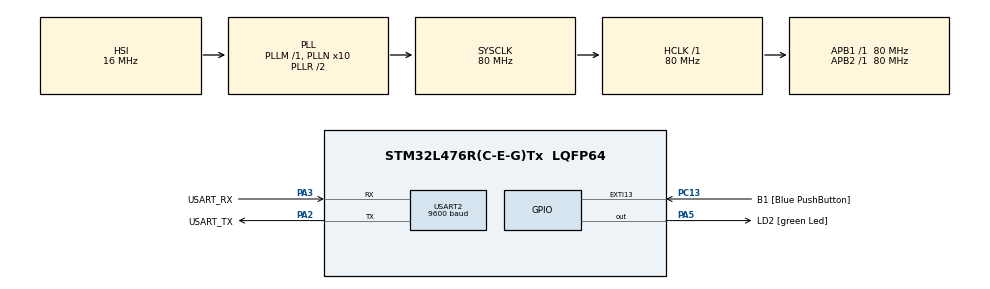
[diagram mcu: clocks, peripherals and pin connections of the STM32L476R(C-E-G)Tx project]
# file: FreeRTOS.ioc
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Mcu.Family=STM32L4
PA2.GPIO_PuPd=GPIO_NOPULL
VP_SYS_VS_tim6.Mode=TIM6
RCC.CortexFreq_Value=80000000
NVIC.TIM6_DAC_IRQn=true\:0\:0\:false\:false\:true\:false\:false\:true
PH0-OSC_IN\ (PH0).Signal=RCC_OSC_IN
PA3.GPIO_PuPd=GPIO_NOPULL
PA2.GPIO_Speed=GPIO_SPEED_FREQ_VERY_HIGH
PC15-OSC32_OUT\ (PC15).Mode=LSE-External-Oscillator
PC13.GPIO_Label=B1 [Blue PushButton]
PA3.GPIO_Speed=GPIO_SPEED_FREQ_VERY_HIGH
RCC.SYSCLKSource=RCC_SYSCLKSOURCE_PLLCLK
ProjectManager.StackSize=0x400
PB3\ (JTDO-TRACESWO).Signal=SYS_JTDO-SWO
PC14-OSC32_IN\ (PC14).Mode=LSE-External-Oscillator
VP_FREERTOS_VS_CMSIS_V2.Mode=CMSIS_V2
PA14\ (JTCK-SWCLK).Signal=SYS_JTCK-SWCLK
RCC.HCLKFreq_Value=80000000
RCC.APB2TimFreq_Value=80000000
RCC.AHBFreq_Value=80000000
RCC.PREFETCH_ENABLE=1
RCC.HSE_VALUE=8000000
USART2.VirtualMode-Asynchronous=VM_ASYNC
PA5.GPIO_PuPd=GPIO_NOPULL
PC13.GPIO_PuPd=GPIO_NOPULL
Mcu.Package=LQFP64
NVIC.TimeBase=TIM6_DAC_IRQn
PA2.GPIO_Label=USART_TX
NVIC.TimeBaseIP=TIM6
RCC.APB1TimFreq_Value=80000000
PA13\ (JTMS-SWDIO).Signal=SYS_JTMS-SWDIO
PA3.Signal=USART2_RX
PA2.GPIO_Mode=GPIO_MODE_AF_PP
RCC.MSI_VALUE=4000000
RCC.PLLSourceVirtual=RCC_PLLSOURCE_HSI
PA14\ (JTCK-SWCLK).Mode=Serial_Wire
FREERTOS.Tasks01=blink01,24,128,StartBlink01,Default,NULL,Dynamic,NULL,NULL;blink02,16,128,StartBlink02,Default,NULL,Dynamic,NULL,NULL
PC13.Signal=GPXTI13
PC15-OSC32_OUT\ (PC15).Signal=RCC_OSC32_OUT
PA14\ (JTCK-SWCLK).GPIO_Label=TCK
PB3\ (JTDO-TRACESWO).GPIO_Label=SWO
USART2.BaudRate=9600
PH1-OSC_OUT\ (PH1).Signal=RCC_OSC_OUT
PA3.Mode=Asynchronous
ProjectManager.TargetToolchain=STM32CubeIDE
PA3.GPIO_Mode=GPIO_MODE_AF_PP
RCC.USBFreq_Value=64000000
PA5.Signal=GPIO_Output
board=NUCLEO-L476RG
RCC.VCOOutputFreq_Value=160000000
RCC.APB2Freq_Value=80000000
PA5.GPIO_ModeDefaultOutputPP=GPIO_MODE_OUTPUT_PP
PA13\ (JTMS-SWDIO).GPIO_Label=TMS
RCC.ADCFreq_Value=64000000
Mcu.Name=STM32L476R(C-E-G)Tx
PA2.Signal=USART2_TX
PA13\ (JTMS-SWDIO).Mode=Serial_Wire
RCC.SYSCLKFreq_VALUE=80000000
PA5.GPIO_Label=LD2 [green Led]
PC13.GPIO_ModeDefaultEXTI=GPIO_MODE_IT_FALLING
PC14-OSC32_IN\ (PC14).Signal=RCC_OSC32_IN
ProjectManager.HeapSize=0x200
RCC.HSI_VALUE=16000000
PA5.GPIO_Speed=GPIO_SPEED_FREQ_LOW
NVIC.PriorityGroup=NVIC_PRIORITYGROUP_4
RCC.PLLN=10
PA2.Mode=Asynchronous
RCC.APB1Freq_Value=80000000
PA3.GPIO_Label=USART_RX

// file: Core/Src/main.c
/* USER CODE BEGIN Header */
/**
  ******************************************************************************
  * @file           : main.c
  * @brief          : Main program body
  ******************************************************************************
  * @attention
  *
  * <h2><center>&copy; Copyright (c) 2021 STMicroelectronics.
  * All rights reserved.</center></h2>
  *
  * This software component is licensed by ST under BSD 3-Clause license,
  * the "License"; You may not use this file except in compliance with the
  * License. You may obtain a copy of the License at:
  *                        opensource.org/licenses/BSD-3-Clause
  *
  ******************************************************************************
  */
/* USER CODE END Header */
#include "main.h"
#include "cmsis_os.h"

/* USER CODE BEGIN Includes */
#include "debug.h"
/* USER CODE END Includes */

UART_HandleTypeDef huart2;

/* Definitions for blink01 */
osThreadId_t blink01Handle;
const osThreadAttr_t blink01_attributes = {
  .name = "blink01",
  .stack_size = 128 * 4,
  .priority = (osPriority_t) osPriorityNormal,
};
/* Definitions for blink02 */
osThreadId_t blink02Handle;
const osThreadAttr_t blink02_attributes = {
  .name = "blink02",
  .stack_size = 128 * 4,
  .priority = (osPriority_t) osPriorityBelowNormal,
};

void SystemClock_Config(void);
static void MX_GPIO_Init(void);
static void MX_USART2_UART_Init(void);
void StartBlink01(void *argument);
void StartBlink02(void *argument);

int main(void)
{

  /* MCU Configuration--------------------------------------------------------*/

  /* Reset of all peripherals, Initializes the Flash interface and the Systick. */
  HAL_Init();

  /* Configure the system clock */
  SystemClock_Config();

  /* Initialize all configured peripherals */
  MX_GPIO_Init();
  MX_USART2_UART_Init();

  /* Init scheduler */
  osKernelInitialize();

  /* Create the thread(s) */
  /* creation of blink01 */
  blink01Handle = osThreadNew(StartBlink01, NULL, &blink01_attributes);

  /* creation of blink02 */
  blink02Handle = osThreadNew(StartBlink02, NULL, &blink02_attributes);

  /* Start scheduler */
  osKernelStart();

  /* We should never get here as control is now taken by the scheduler */
  /* Infinite loop */
  while (1)
  {

  }
}

void SystemClock_Config(void)
{
  RCC_OscInitTypeDef RCC_OscInitStruct = {0};
  RCC_ClkInitTypeDef RCC_ClkInitStruct = {0};
  RCC_PeriphCLKInitTypeDef PeriphClkInit = {0};

  /** Initializes the RCC Oscillators according to the specified parameters
  * in the RCC_OscInitTypeDef structure.
  */
  RCC_OscInitStruct.OscillatorType = RCC_OSCILLATORTYPE_HSI;
  RCC_OscInitStruct.HSIState = RCC_HSI_ON;
  RCC_OscInitStruct.HSICalibrationValue = RCC_HSICALIBRATION_DEFAULT;
  RCC_OscInitStruct.PLL.PLLState = RCC_PLL_ON;
  RCC_OscInitStruct.PLL.PLLSource = RCC_PLLSOURCE_HSI;
  RCC_OscInitStruct.PLL.PLLM = 1;
  RCC_OscInitStruct.PLL.PLLN = 10;
  RCC_OscInitStruct.PLL.PLLP = RCC_PLLP_DIV7;
  RCC_OscInitStruct.PLL.PLLQ = RCC_PLLQ_DIV2;
  RCC_OscInitStruct.PLL.PLLR = RCC_PLLR_DIV2;
  if (HAL_RCC_OscConfig(&RCC_OscInitStruct) != HAL_OK)
  {
    Error_Handler();
  }
  /** Initializes the CPU, AHB and APB buses clocks
  */
  RCC_ClkInitStruct.ClockType = RCC_CLOCKTYPE_HCLK|RCC_CLOCKTYPE_SYSCLK
                              |RCC_CLOCKTYPE_PCLK1|RCC_CLOCKTYPE_PCLK2;
  RCC_ClkInitStruct.SYSCLKSource = RCC_SYSCLKSOURCE_PLLCLK;
  RCC_ClkInitStruct.AHBCLKDivider = RCC_SYSCLK_DIV1;
  RCC_ClkInitStruct.APB1CLKDivider = RCC_HCLK_DIV1;
  RCC_ClkInitStruct.APB2CLKDivider = RCC_HCLK_DIV1;

  if (HAL_RCC_ClockConfig(&RCC_ClkInitStruct, FLASH_LATENCY_4) != HAL_OK)
  {
    Error_Handler();
  }
  PeriphClkInit.PeriphClockSelection = RCC_PERIPHCLK_USART2;
  PeriphClkInit.Usart2ClockSelection = RCC_USART2CLKSOURCE_PCLK1;
  if (HAL_RCCEx_PeriphCLKConfig(&PeriphClkInit) != HAL_OK)
  {
    Error_Handler();
  }
  /** Configure the main internal regulator output voltage
  */
  if (HAL_PWREx_ControlVoltageScaling(PWR_REGULATOR_VOLTAGE_SCALE1) != HAL_OK)
  {
    Error_Handler();
  }
}

static void MX_USART2_UART_Init(void)
{

  huart2.Instance = USART2;
  huart2.Init.BaudRate = 9600;
  huart2.Init.WordLength = UART_WORDLENGTH_8B;
  huart2.Init.StopBits = UART_STOPBITS_1;
  huart2.Init.Parity = UART_PARITY_NONE;
  huart2.Init.Mode = UART_MODE_TX_RX;
  huart2.Init.HwFlowCtl = UART_HWCONTROL_NONE;
  huart2.Init.OverSampling = UART_OVERSAMPLING_16;
  huart2.Init.OneBitSampling = UART_ONE_BIT_SAMPLE_DISABLE;
  huart2.AdvancedInit.AdvFeatureInit = UART_ADVFEATURE_NO_INIT;
  if (HAL_UART_Init(&huart2) != HAL_OK)
  {
    Error_Handler();
  }

}

static void MX_GPIO_Init(void)
{
  GPIO_InitTypeDef GPIO_InitStruct = {0};

  /* GPIO Ports Clock Enable */
  __HAL_RCC_GPIOC_CLK_ENABLE();
  __HAL_RCC_GPIOH_CLK_ENABLE();
  __HAL_RCC_GPIOA_CLK_ENABLE();
  __HAL_RCC_GPIOB_CLK_ENABLE();

  /*Configure GPIO pin Output Level */
  HAL_GPIO_WritePin(LD2_GPIO_Port, LD2_Pin, GPIO_PIN_RESET);

  /*Configure GPIO pin : B1_Pin */
  GPIO_InitStruct.Pin = B1_Pin;
  GPIO_InitStruct.Mode = GPIO_MODE_IT_FALLING;
  GPIO_InitStruct.Pull = GPIO_NOPULL;
  HAL_GPIO_Init(B1_GPIO_Port, &GPIO_InitStruct);

  /*Configure GPIO pin : LD2_Pin */
  GPIO_InitStruct.Pin = LD2_Pin;
  GPIO_InitStruct.Mode = GPIO_MODE_OUTPUT_PP;
  GPIO_InitStruct.Pull = GPIO_NOPULL;
  GPIO_InitStruct.Speed = GPIO_SPEED_FREQ_LOW;
  HAL_GPIO_Init(LD2_GPIO_Port, &GPIO_InitStruct);

}

void StartBlink01(void *argument)
{
  /* USER CODE BEGIN 5 */
  /* Infinite loop */
  for(;;)
  {
	  HAL_GPIO_TogglePin(GPIOA, GPIO_PIN_5);
	  osDelay(500);
	  UART_SEND_TXT(&huart2, "Blink01", 1);
  }
  /* USER CODE END 5 */
}

void StartBlink02(void *argument)
{
  /* USER CODE BEGIN StartBlink02 */
  /* Infinite loop */
  for(;;)
  {
	  HAL_GPIO_TogglePin(GPIOA, GPIO_PIN_5);
	  osDelay(600);
	  UART_SEND_TXT(&huart2, "Blink02", 1);
  }
  /* USER CODE END StartBlink02 */
}

 /**
  * @brief  Period elapsed callback in non blocking mode
  * @note   This function is called  when TIM6 interrupt took place, inside
  * HAL_TIM_IRQHandler(). It makes a direct call to HAL_IncTick() to increment
  * a global variable "uwTick" used as application time base.
  * @param  htim : TIM handle
  * @retval None
  */
void HAL_TIM_PeriodElapsedCallback(TIM_HandleTypeDef *htim)
{
  if (htim->Instance == TIM6) {
    HAL_IncTick();
  }
}

void Error_Handler(void)
{
  __disable_irq();
  while (1)
  {
  }
}

/************************ (C) COPYRIGHT STMicroelectronics *****END OF FILE****/
